# MDR1986VE94 register map
Vendor: Milandr; File version: 1.0
CPU: CM3 r1p1, little endian, MPU, no FPU, 3 interrupt priority bits
Registers are 32-bit, read-write, reset 0x0 unless marked. A register's access mark holds for its fields unless they carry their own. Offsets are from the block's base; [hi:lo] are bit positions; {n}, {i} and the like mark numbered series; 'fields as' and 'values as' point back to an identical list.

## MDR_POWER — POWER
Base 0x40058000; register names take the prefix MDR_POWER_
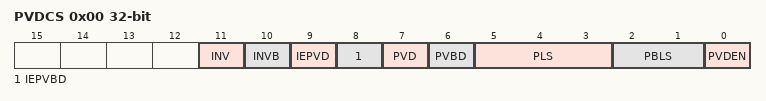
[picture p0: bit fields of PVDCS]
0x00 PVDCS — POWER Power Detector Control/Status Register
  [11] INV, [10] INVB, [9] IEPVD, [8] IEPVBD, [7] PVD, [6] PVBD, [5:3] PLS, [2:1] PBLS, [0] PVDEN

## MDR_WWDG — WWDT
Base 0x40060000; register names take the prefix MDR_WWDG_
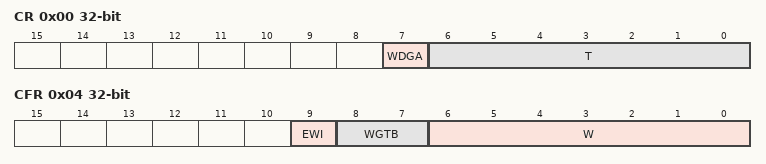
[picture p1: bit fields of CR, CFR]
0x00 CR — WWDG Command Register
  [7] WDGA, [6:0] T
0x04 CFR — WWDG Configuration Register
  [9] EWI, [8:7] WGTB, [6:0] W
0x08 SR — WWDG Status Register
  [0] EWIF

## MDR_IWDG — IWDT
Base 0x40068000; register names take the prefix MDR_IWDG_
0x00 KR — IWDG Key Register
  [15:0] KEY
0x04 PR — IWDG Clock Prescaler Register
  [2:0] PR
0x08 RLR — IWDG Reload Register
  [11:0] RLR
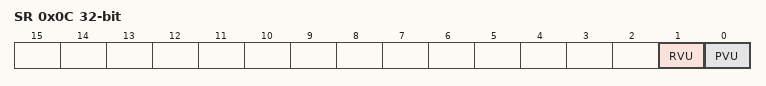
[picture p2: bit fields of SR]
0x0C SR — IWDG Status Register
  [1] RVU, [0] PVU

## MDR_TIMER1 — TIMER1
Base 0x40070000; register names take the prefix MDR_TIMER1_
Same registers: MDR_TIMER2 0x40078000 (register names take the prefix MDR_TIMER2_), MDR_TIMER3 0x40080000 (register names take the prefix MDR_TIMER3_)
0x00 CNT — Timer Counter Register
  [15:0] CNT
0x04 PSG — Timer Clock Prescaler Register
  [15:0] PSG
0x08 ARR — Timer Auto-Reload Register
  [15:0] ARR
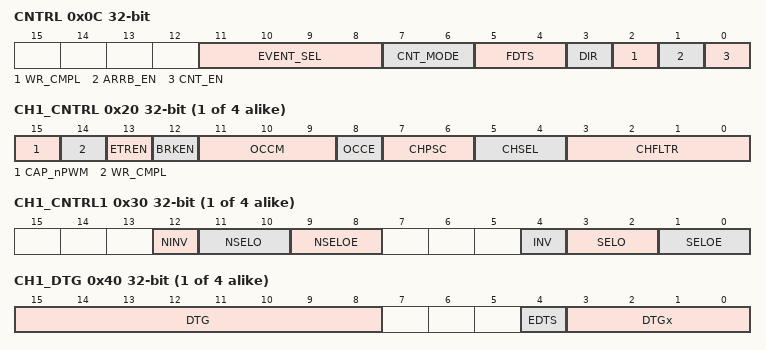
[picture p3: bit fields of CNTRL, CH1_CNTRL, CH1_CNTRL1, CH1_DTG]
0x0C CNTRL — Timer Control Register
  [11:8] EVENT_SEL, [7:6] CNT_MODE, [5:4] FDTS, [3] DIR, [2] WR_CMPL, [1] ARRB_EN, [0] CNT_EN
{0xC+4i} CCR{i} (i=1..4) — Timer Capture/Compare Register
  [15:0] CCR
{0x1C+4i} CH{i}_CNTRL (i=1..4) — Timer Channel Control Register
  [15] CAP_nPWM, [14] WR_CMPL, [13] ETREN, [12] BRKEN, [11:9] OCCM, [8] OCCE, [7:6] CHPSC, [5:4] CHSEL, [3:0] CHFLTR
{0x2C+4i} CH{i}_CNTRL1 (i=1..4) — Timer Channel Control1 Register
  [12] NINV, [11:10] NSELO, [9:8] NSELOE, [4] INV, [3:2] SELO, [1:0] SELOE
{0x3C+4i} CH{i}_DTG (i=1..4) — Timer Channel DTG Register
  [15:8] DTG, [4] EDTS, [3:0] DTGx
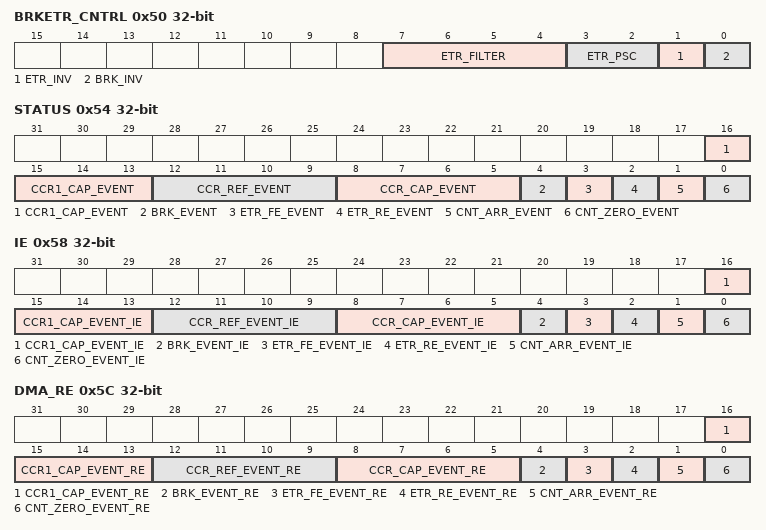
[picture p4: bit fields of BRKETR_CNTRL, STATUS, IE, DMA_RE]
0x50 BRKETR_CNTRL — Timer BRK/ETR Control Register
  [7:4] ETR_FILTER, [3:2] ETR_PSC, [1] ETR_INV, [0] BRK_INV
0x54 STATUS — Timer Status Register
  [16:13] CCR1_CAP_EVENT, [12:9] CCR_REF_EVENT, [8:5] CCR_CAP_EVENT, [4] BRK_EVENT, [3] ETR_FE_EVENT, [2] ETR_RE_EVENT, [1] CNT_ARR_EVENT, [0] CNT_ZERO_EVENT
0x58 IE — Timer Interrupt Enable Register
  [16:13] CCR1_CAP_EVENT_IE, [12:9] CCR_REF_EVENT_IE, [8:5] CCR_CAP_EVENT_IE, [4] BRK_EVENT_IE, [3] ETR_FE_EVENT_IE, [2] ETR_RE_EVENT_IE, [1] CNT_ARR_EVENT_IE, [0] CNT_ZERO_EVENT_IE
0x5C DMA_RE — Timer DMA Request Enable Register
  [16:13] CCR1_CAP_EVENT_RE, [12:9] CCR_REF_EVENT_RE, [8:5] CCR_CAP_EVENT_RE, [4] BRK_EVENT_RE, [3] ETR_FE_EVENT_RE, [2] ETR_RE_EVENT_RE, [1] CNT_ARR_EVENT_RE, [0] CNT_ZERO_EVENT_RE
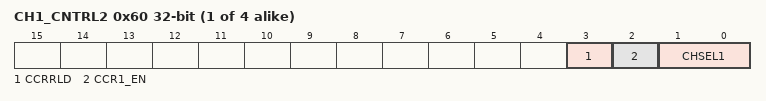
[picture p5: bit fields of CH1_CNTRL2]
{0x5C+4i} CH{i}_CNTRL2 (i=1..4) — Timer Channel Control2 Register
  [3] CCRRLD, [2] CCR1_EN, [1:0] CHSEL1
0x70 CCR11 — Timer Capture/Compare1 Register
  [15:0] CCR
0x74 CCR21 — Timer Capture/Compare1 Register
  [15:0] CCR
0x78 CCR31 — Timer Capture/Compare1 Register
  [15:0] CCR
0x7C CCR41 — Timer Capture/Compare1 Register
  [15:0] CCR

## MDR_ADC — ADC
Base 0x40088000; register names take the prefix MDR_ADC_
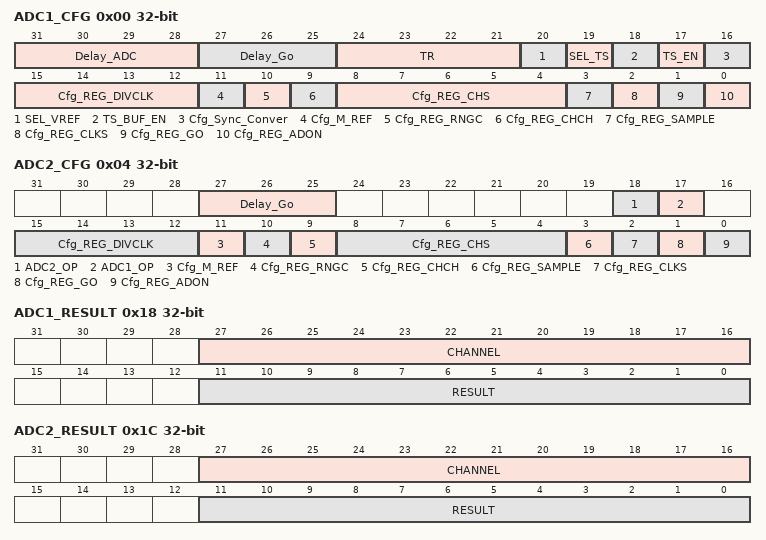
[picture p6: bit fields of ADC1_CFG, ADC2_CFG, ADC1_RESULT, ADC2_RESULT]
0x00 ADC1_CFG — ADC1 Configuration Register
  [31:28] Delay_ADC, [27:25] Delay_Go, [24:21] TR, [20] SEL_VREF, [19] SEL_TS, [18] TS_BUF_EN, [17] TS_EN, [16] Cfg_Sync_Conver, [15:12] Cfg_REG_DIVCLK, [11] Cfg_M_REF, [10] Cfg_REG_RNGC, [9] Cfg_REG_CHCH, [8:4] Cfg_REG_CHS, [3] Cfg_REG_SAMPLE, [2] Cfg_REG_CLKS, [1] Cfg_REG_GO, [0] Cfg_REG_ADON
0x04 ADC2_CFG — ADC2 Configuration Register
  [27:25] Delay_Go, [18] ADC2_OP, [17] ADC1_OP, [15:12] Cfg_REG_DIVCLK, [11] Cfg_M_REF, [10] Cfg_REG_RNGC, [9] Cfg_REG_CHCH, [8:4] Cfg_REG_CHS, [3] Cfg_REG_SAMPLE, [2] Cfg_REG_CLKS, [1] Cfg_REG_GO, [0] Cfg_REG_ADON
0x08 ADC1_H_LEVEL — ADC1 High Level Register
  [11:0] REG_H_LEVEL
0x0C ADC2_H_LEVEL — ADC2 High Level Register
  [11:0] REG_H_LEVEL
0x10 ADC1_L_LEVEL — ADC1 Low Level Register
  [11:0] REG_L_LEVEL
0x14 ADC2_L_LEVEL — ADC2 Low Level Register
  [11:0] REG_L_LEVEL
0x18 ADC1_RESULT
  [27:16] CHANNEL, [11:0] RESULT
0x1C ADC2_RESULT
  [27:16] CHANNEL, [11:0] RESULT
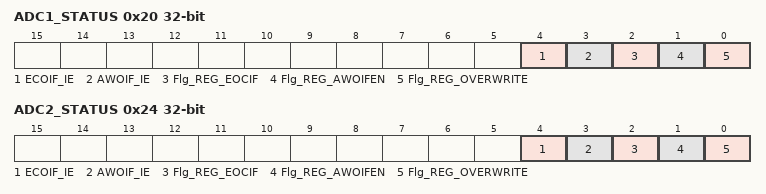
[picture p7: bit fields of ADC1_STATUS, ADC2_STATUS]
0x20 ADC1_STATUS
  [4] ECOIF_IE, [3] AWOIF_IE, [2] Flg_REG_EOCIF, [1] Flg_REG_AWOIFEN, [0] Flg_REG_OVERWRITE
0x24 ADC2_STATUS
  fields as ADC1_STATUS
0x28 ADC1_CHSEL — ADC1 Channel Selector Register
  [31:0] Sl_Ch_Ch_REF
0x2C ADC2_CHSEL — ADC2 Channel Selector Register
  [31:0] Sl_Ch_Ch_REF

## MDR_DAC — DAC
Base 0x40090000; register names take the prefix MDR_DAC_
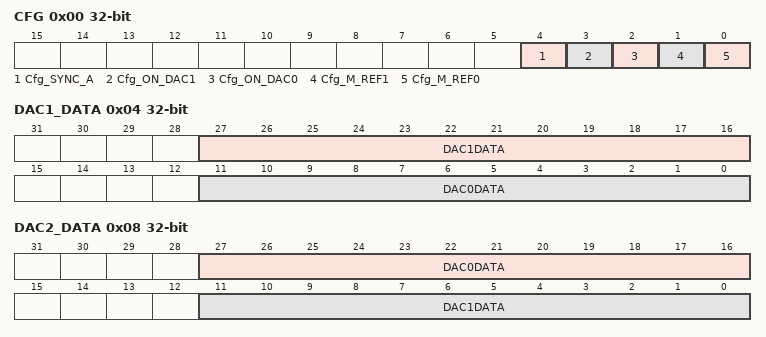
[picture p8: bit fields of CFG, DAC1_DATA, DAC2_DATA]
0x00 CFG — DAC Configuration Register
  [4] Cfg_SYNC_A, [3] Cfg_ON_DAC1, [2] Cfg_ON_DAC0, [1] Cfg_M_REF1, [0] Cfg_M_REF0
0x04 DAC1_DATA
  [27:16] DAC1DATA, [11:0] DAC0DATA
0x08 DAC2_DATA
  [27:16] DAC0DATA, [11:0] DAC1DATA

## MDR_COMP — COMPARATOR
Base 0x40098000; register names take the prefix MDR_COMP_
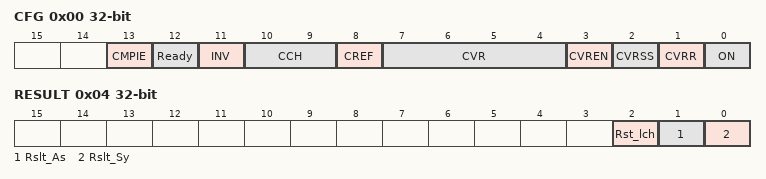
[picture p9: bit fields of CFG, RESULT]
0x00 CFG — COMP Configuration Register
  [13] CMPIE, [12] Ready, [11] INV, [10:9] CCH, [8] CREF, [7:4] CVR, [3] CVREN, [2] CVRSS, [1] CVRR, [0] ON
0x04 RESULT — COMP Result Register
  [2] Rst_lch, [1] Rslt_As, [0] Rslt_Sy
0x08 RESULT_LATCH — COMP Result Latch Register
  [0] Rst_lch

## MDR_PORTA — PORTA
Base 0x400A8000; register names take the prefix MDR_PORTA_
Same registers: MDR_PORTB 0x400B0000 (register names take the prefix MDR_PORTB_), MDR_PORTC 0x400B8000 (register names take the prefix MDR_PORTC_), MDR_PORTD 0x400C0000 (register names take the prefix MDR_PORTD_), MDR_PORTE 0x400C8000 (register names take the prefix MDR_PORTE_), MDR_PORTF 0x400E8000 (register names take the prefix MDR_PORTF_)
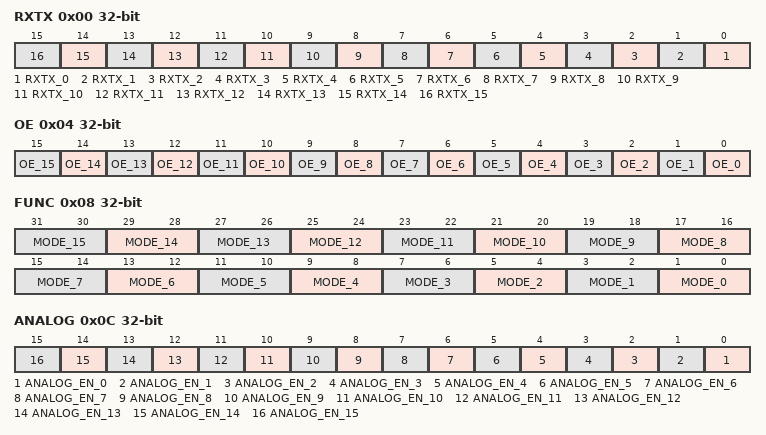
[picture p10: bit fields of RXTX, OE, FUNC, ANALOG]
0x00 RXTX — PORT Data Register
  [n] RXTX_{n} (n=0..15)
0x04 OE — PORT Output Enable Register
  [n] OE_{n} (n=0..15)
0x08 FUNC — PORT Function Register
  [2n+1:2n] MODE_{n} (n=0..15)
0x0C ANALOG — PORT Analog Function Register
  [n] ANALOG_EN_{n} (n=0..15)
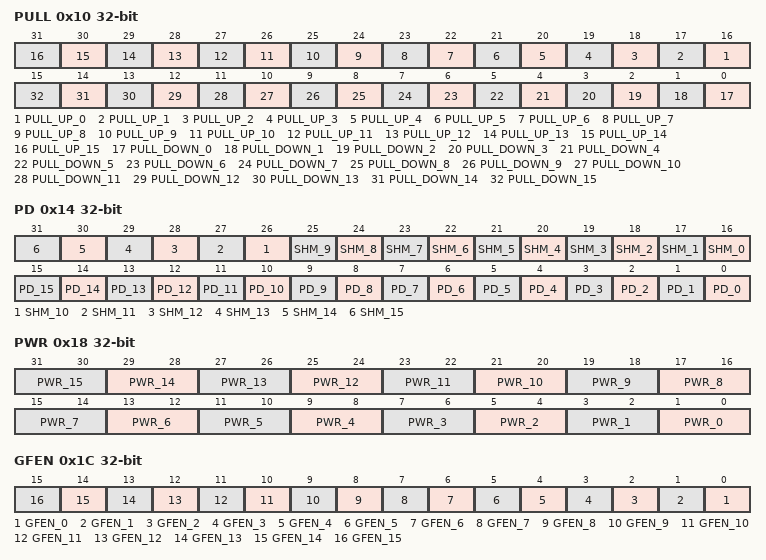
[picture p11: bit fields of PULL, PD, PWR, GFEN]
0x10 PULL — PORT Pull Up/Down Register
  [n+16] PULL_UP_{n} (n=0..15), [n] PULL_DOWN_{n} (n=0..15)
0x14 PD — PORT Driver Mode Register
  [n+16] SHM_{n} (n=0..15), [n] PD_{n} (n=0..15)
0x18 PWR — PORT Power Register
  [2n+1:2n] PWR_{n} (n=0..15)
0x1C GFEN — PORT Filter Configuration Register
  [n] GFEN_{n} (n=0..15)

## MDR_BKP — BACKUP
Base 0x400D8000; register names take the prefix MDR_BKP_
{0x0+4i} REG_{i:02} (i=0..9) — Backup Register {i}
  [31:0] BKP_REG
0x28 REG_0A — Backup Register 10
  [31:0] BKP_REG
0x2C REG_0B — Backup Register 11
  [31:0] BKP_REG
0x30 REG_0C — Backup Register 12
  [31:0] BKP_REG
0x34 REG_0D — Backup Register 13
  [31:0] BKP_REG
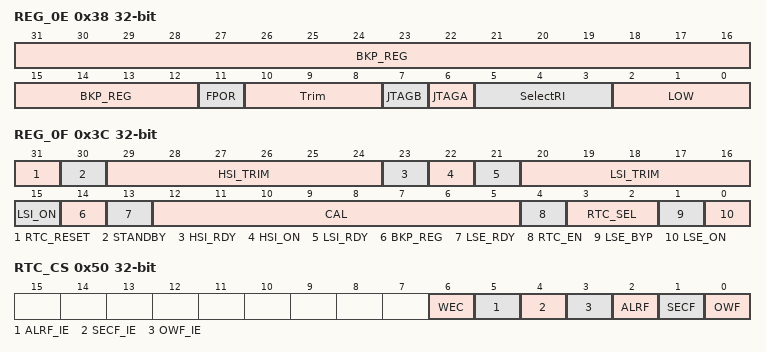
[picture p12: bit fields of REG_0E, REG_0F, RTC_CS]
0x38 REG_0E — Backup Register 14
  [31:12] BKP_REG, [11] FPOR, [10:8] Trim, [7] JTAGB, [6] JTAGA, [5:3] SelectRI, [2:0] LOW
0x3C REG_0F — Backup Register 15
  [31] RTC_RESET, [30] STANDBY, [29:24] HSI_TRIM, [23] HSI_RDY, [22] HSI_ON, [21] LSI_RDY, [20:16] LSI_TRIM, [15] LSI_ON, [14] BKP_REG, [13] LSE_RDY, [12:5] CAL, [4] RTC_EN, [3:2] RTC_SEL, [1] LSE_BYP, [0] LSE_ON
0x40 RTC_CNT — Realtime Clock Counter Register
0x44 RTC_DIV — Realtime Prescaler Counter Register
  [19:0] RTC_DIV
0x48 RTC_PRL — Realtime Prescaler Auto-Reload Value Register
  [19:0] RTC_PRL
0x4C RTC_ALRM — Realtime Alarm Register
0x50 RTC_CS — Backup Realtime clock Register
  [6] WEC, [5] ALRF_IE, [4] SECF_IE, [3] OWF_IE, [2] ALRF, [1] SECF, [0] OWF

## MDR_EBC — EBC
Base 0x400F0000; register names take the prefix MDR_EBC_
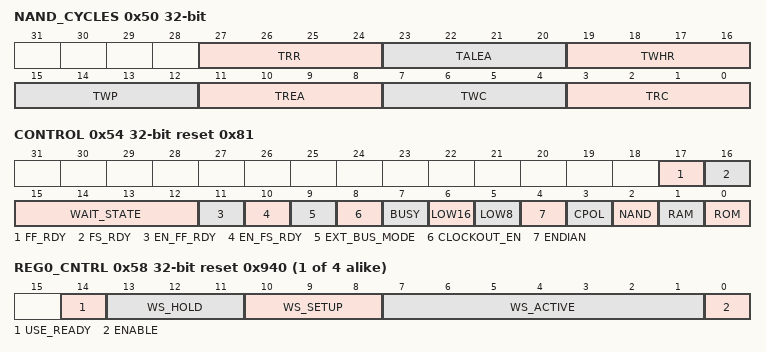
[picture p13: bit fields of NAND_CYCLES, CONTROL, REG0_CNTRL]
0x50 NAND_CYCLES — EBC NAND Timing Register
  [27:24] TRR, [23:20] TALEA, [19:16] TWHR, [15:12] TWP, [11:8] TREA, [7:4] TWC, [3:0] TRC
0x54 CONTROL reset 0x81 — EBC Control Register
  [17] FF_RDY, [16] FS_RDY, [15:12] WAIT_STATE, [11] EN_FF_RDY, [10] EN_FS_RDY, [9] EXT_BUS_MODE, [8] CLOCKOUT_EN, [7] BUSY, [6] LOW16, [5] LOW8, [4] ENDIAN, [3] CPOL, [2] NAND, [1] RAM, [0] ROM
{0x58+4i} REG{i}_CNTRL reset 0x940 (i=0..3) — EBC Region {i} Control Register
  [14] USE_READY, [13:11] WS_HOLD, [10:8] WS_SETUP, [7:1] WS_ACTIVE, [0] ENABLE
